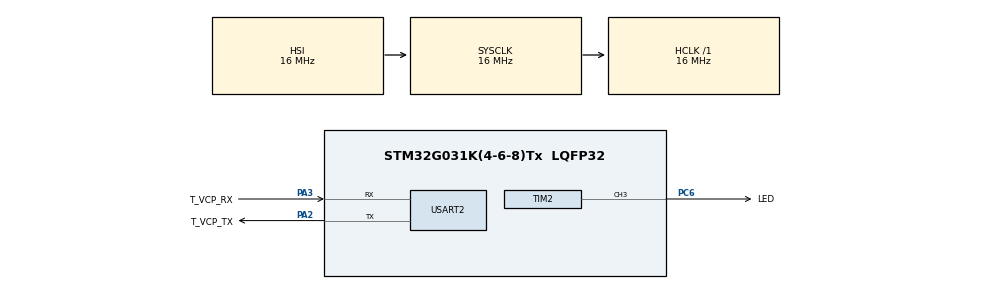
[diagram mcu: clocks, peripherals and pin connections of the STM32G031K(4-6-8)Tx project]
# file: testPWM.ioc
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Mcu.Family=STM32G0
Mcu.Name=STM32G031K(4-6-8)Tx
Mcu.Package=LQFP32
PA13.GPIO_Label=T_JTMS
PA13.Mode=Serial_Wire
PA13.Signal=SYS_SWDIO
PA14-BOOT0.GPIO_Label=T_JTCK
PA14-BOOT0.Mode=Serial_Wire
PA14-BOOT0.Signal=SYS_SWCLK
PA2.GPIO_Label=T_VCP_TX
PA2.GPIO_PuPd=GPIO_PULLUP
PA2.Mode=Asynchronous
PA2.Signal=USART2_TX
PA3.GPIO_Label=T_VCP_RX
PA3.GPIO_PuPd=GPIO_PULLUP
PA3.Mode=Asynchronous
PA3.Signal=USART2_RX
PC14-OSC32_IN\ (PC14).Mode=LSE-External-Oscillator
PC14-OSC32_IN\ (PC14).Signal=RCC_OSC32_IN
PC15-OSC32_OUT\ (PC15).Mode=LSE-External-Oscillator
PC15-OSC32_OUT\ (PC15).Signal=RCC_OSC32_OUT
PC6.GPIO_Label=LED
PC6.Signal=S_TIM2_CH3
ProjectManager.HeapSize=0x200
ProjectManager.StackSize=0x400
ProjectManager.TargetToolchain=STM32CubeIDE
RCC.AHBFreq_Value=16000000
RCC.CortexFreq_Value=16000000
RCC.EXTERNAL_CLOCK_VALUE=12288000
RCC.HCLKFreq_Value=16000000
RCC.HSE_VALUE=8000000
RCC.HSI_VALUE=16000000
RCC.SYSCLKFreq_VALUE=16000000
RCC.VCOOutputFreq_Value=128000000
SH.S_TIM2_CH3.0=TIM2_CH3,PWM Generation3 CH3
TIM2.AutoReloadPreload=TIM_AUTORELOAD_PRELOAD_ENABLE
TIM2.Channel-PWM\ Generation3\ CH3=TIM_CHANNEL_3
TIM2.Period=0
TIM2.Prescaler=255
TIM2.Pulse-PWM\ Generation3\ CH3=32765
USART2.VirtualMode-Asynchronous=VM_ASYNC
USART2.WordLength=WORDLENGTH_7B
board=NUCLEO-G031K8

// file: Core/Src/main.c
/* USER CODE BEGIN Header */
/**
  ******************************************************************************
  * @file           : main.c
  * @brief          : Main program body
  ******************************************************************************
  * @attention
  *
  * <h2><center>&copy; Copyright (c) 2022 STMicroelectronics.
  * All rights reserved.</center></h2>
  *
  * This software component is licensed by ST under BSD 3-Clause license,
  * the "License"; You may not use this file except in compliance with the
  * License. You may obtain a copy of the License at:
  *                        opensource.org/licenses/BSD-3-Clause
  *
  ******************************************************************************
  */
/* USER CODE END Header */

#include "main.h"

TIM_HandleTypeDef htim2;

UART_HandleTypeDef huart2;

void SystemClock_Config(void);
static void MX_GPIO_Init(void);
static void MX_USART2_UART_Init(void);
static void MX_TIM2_Init(void);
/* USER CODE BEGIN PFP */
static void setPWM(TIM_HandleTypeDef*, uint32_t, uint16_t, uint16_t);
/* USER CODE END PFP */

int main(void)
{

  /* MCU Configuration--------------------------------------------------------*/

  /* Reset of all peripherals, Initializes the Flash interface and the Systick. */
  HAL_Init();

  /* Configure the system clock */
  SystemClock_Config();

  /* Initialize all configured peripherals */
  MX_GPIO_Init();
  MX_USART2_UART_Init();
  MX_TIM2_Init();
  /* USER CODE BEGIN 2 */

  HAL_TIM_PWM_Start(&htim2, TIM_CHANNEL_3);
  //setPWM(&htim2, TIM_CHANNEL_3, 65535, 32767);
  /* USER CODE END 2 */

  /* Infinite loop */
  while (1)
  {

    /* USER CODE BEGIN 3 */

//      for (int i = 0; i < 65535; i ++) {
//          ;
//      }
//      HAL_GPIO_WritePin(LED_GPIO_Port, LED_Pin, GPIO_PIN_SET);
//
//      for (int i = 0; i < 65535; i ++) {
//          ;
//      }
//      HAL_GPIO_WritePin(LED_GPIO_Port, LED_Pin, GPIO_PIN_RESET);
  }
  /* USER CODE END 3 */
}

void SystemClock_Config(void)
{
  RCC_OscInitTypeDef RCC_OscInitStruct = {0};
  RCC_ClkInitTypeDef RCC_ClkInitStruct = {0};

  /** Configure the main internal regulator output voltage
  */
  HAL_PWREx_ControlVoltageScaling(PWR_REGULATOR_VOLTAGE_SCALE1);
  /** Initializes the CPU, AHB and APB busses clocks
  */
  RCC_OscInitStruct.OscillatorType = RCC_OSCILLATORTYPE_HSI;
  RCC_OscInitStruct.HSIState = RCC_HSI_ON;
  RCC_OscInitStruct.HSIDiv = RCC_HSI_DIV1;
  RCC_OscInitStruct.HSICalibrationValue = RCC_HSICALIBRATION_DEFAULT;
  RCC_OscInitStruct.PLL.PLLState = RCC_PLL_NONE;
  if (HAL_RCC_OscConfig(&RCC_OscInitStruct) != HAL_OK)
  {
    Error_Handler();
  }
  /** Initializes the CPU, AHB and APB busses clocks
  */
  RCC_ClkInitStruct.ClockType = RCC_CLOCKTYPE_HCLK|RCC_CLOCKTYPE_SYSCLK
                              |RCC_CLOCKTYPE_PCLK1;
  RCC_ClkInitStruct.SYSCLKSource = RCC_SYSCLKSOURCE_HSI;
  RCC_ClkInitStruct.AHBCLKDivider = RCC_SYSCLK_DIV1;
  RCC_ClkInitStruct.APB1CLKDivider = RCC_HCLK_DIV1;

  if (HAL_RCC_ClockConfig(&RCC_ClkInitStruct, FLASH_LATENCY_0) != HAL_OK)
  {
    Error_Handler();
  }
}

static void MX_TIM2_Init(void)
{

  TIM_MasterConfigTypeDef sMasterConfig = {0};
  TIM_OC_InitTypeDef sConfigOC = {0};

  htim2.Instance = TIM2;
  htim2.Init.Prescaler = 255;
  htim2.Init.CounterMode = TIM_COUNTERMODE_UP;
  htim2.Init.Period = 65535;
  htim2.Init.ClockDivision = TIM_CLOCKDIVISION_DIV1;
  htim2.Init.AutoReloadPreload = TIM_AUTORELOAD_PRELOAD_ENABLE;
  if (HAL_TIM_PWM_Init(&htim2) != HAL_OK)
  {
    Error_Handler();
  }
  sMasterConfig.MasterOutputTrigger = TIM_TRGO_RESET;
  sMasterConfig.MasterSlaveMode = TIM_MASTERSLAVEMODE_DISABLE;
  if (HAL_TIMEx_MasterConfigSynchronization(&htim2, &sMasterConfig) != HAL_OK)
  {
    Error_Handler();
  }
  sConfigOC.OCMode = TIM_OCMODE_PWM1;
  sConfigOC.Pulse = htim2.Init.Period / 4;
  sConfigOC.OCPolarity = TIM_OCPOLARITY_HIGH;
  sConfigOC.OCFastMode = TIM_OCFAST_DISABLE;
  if (HAL_TIM_PWM_ConfigChannel(&htim2, &sConfigOC, TIM_CHANNEL_3) != HAL_OK)
  {
    Error_Handler();
  }
  HAL_TIM_MspPostInit(&htim2);

}

static void MX_USART2_UART_Init(void)
{

  huart2.Instance = USART2;
  huart2.Init.BaudRate = 115200;
  huart2.Init.WordLength = UART_WORDLENGTH_7B;
  huart2.Init.StopBits = UART_STOPBITS_1;
  huart2.Init.Parity = UART_PARITY_NONE;
  huart2.Init.Mode = UART_MODE_TX_RX;
  huart2.Init.HwFlowCtl = UART_HWCONTROL_NONE;
  huart2.Init.OverSampling = UART_OVERSAMPLING_16;
  huart2.Init.OneBitSampling = UART_ONE_BIT_SAMPLE_DISABLE;
  huart2.Init.ClockPrescaler = UART_PRESCALER_DIV1;
  huart2.AdvancedInit.AdvFeatureInit = UART_ADVFEATURE_NO_INIT;
  if (HAL_UART_Init(&huart2) != HAL_OK)
  {
    Error_Handler();
  }

}

static void MX_GPIO_Init(void)
{

  /* GPIO Ports Clock Enable */
  __HAL_RCC_GPIOC_CLK_ENABLE();
  __HAL_RCC_GPIOA_CLK_ENABLE();

}

/* USER CODE BEGIN 4 */

void setPWM(TIM_HandleTypeDef* timer, uint32_t channel, uint16_t period, uint16_t pulse)
{
 HAL_TIM_PWM_Stop(timer, channel); // stop generation of pwm
 TIM_OC_InitTypeDef sConfigOC;
 timer->Init.Period = period; // set the period duration

 HAL_TIM_PWM_Init(timer); // reinititialise with new period value
 sConfigOC.OCMode = TIM_OCMODE_PWM1;
 sConfigOC.Pulse = pulse; // set the pulse duration
 sConfigOC.OCPolarity = TIM_OCPOLARITY_HIGH;
 sConfigOC.OCFastMode = TIM_OCFAST_DISABLE;
 HAL_TIM_PWM_ConfigChannel(timer, &sConfigOC, channel);
 HAL_TIM_PWM_Start(timer, channel); // start pwm generation
}

/* USER CODE END 4 */

void Error_Handler(void)
{
}

/************************ (C) COPYRIGHT STMicroelectronics *****END OF FILE****/
